AUTOSAR XML (schema 4-2-2)
package /STELLANTIS/EPT/ASWCs
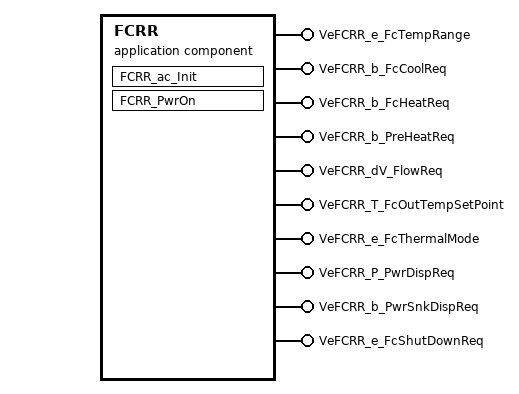
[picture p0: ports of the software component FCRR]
  application sw component type FCRR
    10 x provide port:
      VeFCRR_e_FcTempRange: nonqueued-sender-com-spec{data-element=Value, init-value=CeFCRR_e_Nominal}, provided-interface=VeFCRR_e_FcTempRange
      VeFCRR_b_FcCoolReq: nonqueued-sender-com-spec{data-element=Value, init-value=0}, provided-interface=VeFCRR_b_FcCoolReq
      VeFCRR_b_FcHeatReq: nonqueued-sender-com-spec{data-element=Value, init-value=0}, provided-interface=VeFCRR_b_FcHeatReq
      VeFCRR_b_PreHeatReq: nonqueued-sender-com-spec{data-element=Value, init-value=0}, provided-interface=VeFCRR_b_PreHeatReq
      VeFCRR_dV_FlowReq: nonqueued-sender-com-spec{data-element=Value, init-value=0}, provided-interface=VeFCRR_dV_FlowReq
      VeFCRR_T_FcOutTempSetPoint: nonqueued-sender-com-spec{data-element=Value, init-value=0}, provided-interface=VeFCRR_T_FcOutTempSetPoint
      VeFCRR_e_FcThermalMode: nonqueued-sender-com-spec{data-element=Value, init-value=CeFCRR_e_FC_OFF}, provided-interface=VeFCRR_e_FcThermalMode
      VeFCRR_P_PwrDispReq: nonqueued-sender-com-spec{data-element=Value, init-value=0}, provided-interface=VeFCRR_P_PwrDispReq
      VeFCRR_b_PwrSnkDispReq: nonqueued-sender-com-spec{data-element=Value, init-value=0}, provided-interface=VeFCRR_b_PwrSnkDispReq
      VeFCRR_e_FcShutDownReq: nonqueued-sender-com-spec{data-element=Value, init-value=CeFCRR_e_FcNoFlt}, provided-interface=VeFCRR_e_FcShutDownReq
    behavior IB_FCRR: data-type-mapping=msADTtoIDTMapping, handle-termination-and-restart=NO-SUPPORT
      init event Event_FCRR_ac_Init: start-on-event=FCRR_ac_Init
      init event Event_PwrOn: start-on-event=FCRR_PwrOn
      runnable FCRR_ac_Init
        data-send-points:
          access OUT_VeFCRR_e_FcTempRange_Value: accessed-variable=VeFCRR_e_FcTempRange.Value
          access OUT_VeFCRR_e_FcThermalMode_Value: accessed-variable=VeFCRR_e_FcThermalMode.Value
          access OUT_VeFCRR_e_FcShutDownReq_Value: accessed-variable=VeFCRR_e_FcShutDownReq.Value
      runnable FCRR_PwrOn
        data-send-points:
          10 x access:
            OUT_VeFCRR_e_FcTempRange_Value: accessed-variable=VeFCRR_e_FcTempRange.Value
            OUT_VeFCRR_b_FcCoolReq_Value: accessed-variable=VeFCRR_b_FcCoolReq.Value
            OUT_VeFCRR_b_FcHeatReq_Value: accessed-variable=VeFCRR_b_FcHeatReq.Value
            OUT_VeFCRR_b_PreHeatReq_Value: accessed-variable=VeFCRR_b_PreHeatReq.Value
            OUT_VeFCRR_dV_FlowReq_Value: accessed-variable=VeFCRR_dV_FlowReq.Value
            OUT_VeFCRR_T_FcOutTempSetPoint_Value: accessed-variable=VeFCRR_T_FcOutTempSetPoint.Value
            OUT_VeFCRR_e_FcThermalMode_Value: accessed-variable=VeFCRR_e_FcThermalMode.Value
            OUT_VeFCRR_P_PwrDispReq_Value: accessed-variable=VeFCRR_P_PwrDispReq.Value
            OUT_VeFCRR_b_PwrSnkDispReq_Value: accessed-variable=VeFCRR_b_PwrSnkDispReq.Value
            OUT_VeFCRR_e_FcShutDownReq_Value: accessed-variable=VeFCRR_e_FcShutDownReq.Value
      variation point proxy Variant_FCRR_1: category=CONDITION, condition-access=0
